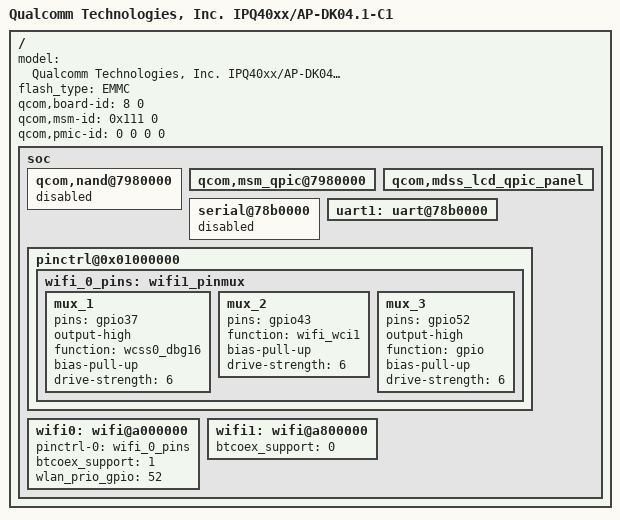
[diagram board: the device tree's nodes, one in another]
/* Copyright (c) 2015, The Linux Foundation. All rights reserved.
 *
 * Permission to use, copy, modify, and/or distribute this software for any
 * purpose with or without fee is hereby granted, provided that the above
 * copyright notice and this permission notice appear in all copies.
 *
 * THE SOFTWARE IS PROVIDED "AS IS" AND THE AUTHOR DISCLAIMS ALL WARRANTIES
 * WITH REGARD TO THIS SOFTWARE INCLUDING ALL IMPLIED WARRANTIES OF
 * MERCHANTABILITY AND FITNESS. IN NO EVENT SHALL THE AUTHOR BE LIABLE FOR
 * ANY SPECIAL, DIRECT, INDIRECT, OR CONSEQUENTIAL DAMAGES OR ANY DAMAGES
 * WHATSOEVER RESULTING FROM LOSS OF USE, DATA OR PROFITS, WHETHER IN AN
 * ACTION OF CONTRACT, NEGLIGENCE OR OTHER TORTIOUS ACTION, ARISING OUT OF
 * OR IN CONNECTION WITH THE USE OR PERFORMANCE OF THIS SOFTWARE.
 *
 */

#include "qcom-ipq40xx-ap.dk04.1_cc.dtsi"
#include "qcom-ipq40xx-lcdc.dtsi"
#include "qcom-ipq40xx-lcdpanel.dtsi"

/ {
	model = "Qualcomm Technologies, Inc. IPQ40xx/AP-DK04.1-C1";
	flash_type = "EMMC";

	qcom,board-id = <8 0>;
	qcom,msm-id = <0x111 0>;
	qcom,pmic-id = <0 0 0 0>;

	soc {
		qcom,nand@7980000 {
			status = "disabled";
		};

		qcom,msm_qpic@7980000 {
			status = "ok";
		};

		qcom,mdss_lcd_qpic_panel {
			status = "ok";
		};

		serial@78b0000 {
			status = "disabled";
		};

		uart1:uart@78b0000 {
			status = "ok";
		};

		pinctrl@0x01000000 {
			wifi_0_pins: wifi1_pinmux {
				mux_1 {
					pins = "gpio37";
					output-high;
					function="wcss0_dbg16";
					bias-pull-up;
					drive-strength = <6>;
				};
				mux_2 {
					pins = "gpio43";
					function="wifi_wci1";
					bias-pull-up;
					drive-strength = <6>;
				};
				mux_3 {
					pins = "gpio52";
					output-high;
					function="gpio";
					bias-pull-up;
					drive-strength = <6>;
				};
			};
		};

		wifi0: wifi@a000000 {
			pinctrl-0 = <&wifi_0_pins>;
			pinctrl-names = "default";
			btcoex_support = <1>;
			wlan_prio_gpio = <52>;
		};

		wifi1: wifi@a800000 {
			btcoex_support = <0>;
		};
	};
};
